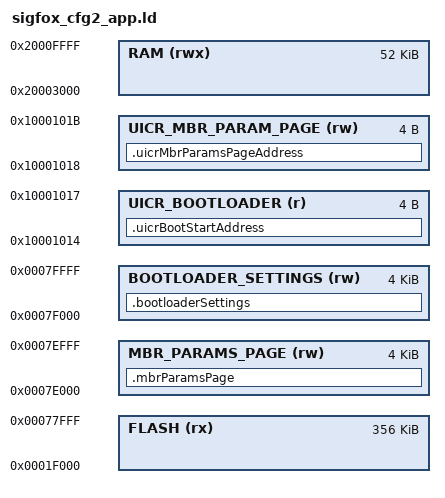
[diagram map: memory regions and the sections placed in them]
/* Linker script to configure memory regions. */

SEARCH_DIR(.)
GROUP(-lgcc -lc -lnosys)

MEMORY
{
  FLASH (rx) : ORIGIN = 0x0001F000, LENGTH = 0x59000
  RAM (rwx) :  ORIGIN = 0x20003000, LENGTH = 0x0D000
  
  /** Location of bootloader setting in flash. */
  BOOTLOADER_SETTINGS (rw) : ORIGIN = 0x0007F000, LENGTH = 0x1000

  /** Location in UICR where bootloader start address is stored. */
  UICR_BOOTLOADER (r) : ORIGIN = 0x10001014, LENGTH = 0x04

  /** Location of mbr params page in flash. */
  MBR_PARAMS_PAGE (rw) : ORIGIN = 0x0007E000, LENGTH = 0x1000

  /** Location in UICR where mbr params page address is stored. */
  UICR_MBR_PARAM_PAGE(rw) : ORIGIN = 0x10001018, LENGTH = 0x04
}

SECTIONS
{
  /* Place the bootloader settings page in flash. */
  .bootloaderSettings(NOLOAD) :
  {

  } > BOOTLOADER_SETTINGS

  /* Write the bootloader address in UICR. */
  .uicrBootStartAddress :
  {
    KEEP(*(.uicrBootStartAddress))
  } > UICR_BOOTLOADER

  /* Place the mbr params page in flash. */
    .mbrParamsPage(NOLOAD) :
  {

  } > MBR_PARAMS_PAGE

  /* Write the bootloader address in UICR. */
  .uicrMbrParamsPageAddress :
  {
    KEEP(*(.uicrMbrParamsPageAddress))
  } > UICR_MBR_PARAM_PAGE

}

SECTIONS
{
  .fs_data :
  {
    PROVIDE(__start_fs_data = .);
    KEEP(*(.fs_data))
    PROVIDE(__stop_fs_data = .);
  } > RAM
} INSERT AFTER .data;

INCLUDE "..\..\..\..\..\..\components\toolchain\gcc\nrf52_common.ld"
